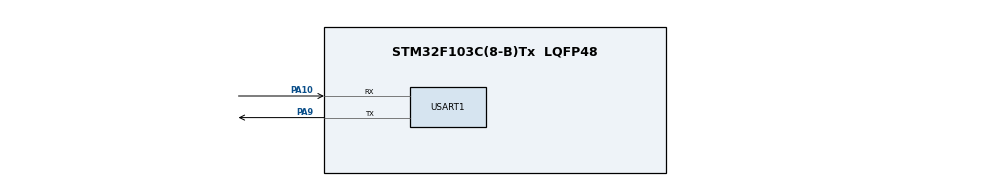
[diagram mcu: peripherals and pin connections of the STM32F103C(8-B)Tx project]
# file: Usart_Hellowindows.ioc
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Mcu.Family=STM32F1
Mcu.Name=STM32F103C(8-B)Tx
Mcu.Package=LQFP48
NVIC.PriorityGroup=NVIC_PRIORITYGROUP_4
NVIC.USART1_IRQn=true\:0\:0\:false\:false\:true\:true\:true\:true
PA10.Mode=Asynchronous
PA10.Signal=USART1_RX
PA13.Mode=Serial_Wire
PA13.Signal=SYS_JTMS-SWDIO
PA14.Mode=Serial_Wire
PA14.Signal=SYS_JTCK-SWCLK
PA9.Mode=Asynchronous
PA9.Signal=USART1_TX
ProjectManager.HeapSize=0x200
ProjectManager.StackSize=0x400
ProjectManager.TargetToolchain=MDK-ARM V5.32
RCC.APB1Freq_Value=8000000
RCC.APB2Freq_Value=8000000
USART1.VirtualMode=VM_ASYNC
board=custom

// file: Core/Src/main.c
/* USER CODE BEGIN Header */
/**
  ******************************************************************************
  * @file           : main.c
  * @brief          : Main program body
  ******************************************************************************
  * @attention
  *
  * Copyright (c) 2023 STMicroelectronics.
  * All rights reserved.
  *
  * This software is licensed under terms that can be found in the LICENSE file
  * in the root directory of this software component.
  * If no LICENSE file comes with this software, it is provided AS-IS.
  *
  ******************************************************************************
  */
/* USER CODE END Header */
#include "main.h"
#include "string.h"

/* USER CODE BEGIN PM */
char message[]="hello Windows!\n";//输出信息
char c;//指令 0:停止  1:开始
char tips[]="CommandError\n";//提示1
char start[]="Start\n";//提示2
char stop[]="Stop\n";//提示3
uint8_t message_flag=0;//标志 0:停止发送 1.开始发送
/* USER CODE END PM */

UART_HandleTypeDef huart1;

void SystemClock_Config(void);
static void MX_GPIO_Init(void);
static void MX_USART1_UART_Init(void);

int main(void)
{
// 初始化STM32和USART
    HAL_Init();
    SystemClock_Config();
    MX_USART1_UART_Init();

    // 启用全局中断
    HAL_NVIC_EnableIRQ(USART1_IRQn);
  /* USER CODE BEGIN 2 */
//设置接受中断
	HAL_UART_Receive_IT(&huart1, (uint8_t *)&c, 1);
  /* USER CODE END 2 */

  /* Infinite loop */
  while (1)
  {
		if (1){
			HAL_UART_Transmit(&huart1, (uint8_t *)&message, strlen(message), 0xFFFF);
		HAL_Delay(1000);
		}
		else {
		}
  }
}

void SystemClock_Config(void)
{
  RCC_OscInitTypeDef RCC_OscInitStruct = {0};
  RCC_ClkInitTypeDef RCC_ClkInitStruct = {0};

  /** Initializes the RCC Oscillators according to the specified parameters
  * in the RCC_OscInitTypeDef structure.
  */
  RCC_OscInitStruct.OscillatorType = RCC_OSCILLATORTYPE_HSI;
  RCC_OscInitStruct.HSIState = RCC_HSI_ON;
  RCC_OscInitStruct.HSICalibrationValue = RCC_HSICALIBRATION_DEFAULT;
  RCC_OscInitStruct.PLL.PLLState = RCC_PLL_NONE;
  if (HAL_RCC_OscConfig(&RCC_OscInitStruct) != HAL_OK)
  {
    Error_Handler();
  }

  /** Initializes the CPU, AHB and APB buses clocks
  */
  RCC_ClkInitStruct.ClockType = RCC_CLOCKTYPE_HCLK|RCC_CLOCKTYPE_SYSCLK
                              |RCC_CLOCKTYPE_PCLK1|RCC_CLOCKTYPE_PCLK2;
  RCC_ClkInitStruct.SYSCLKSource = RCC_SYSCLKSOURCE_HSI;
  RCC_ClkInitStruct.AHBCLKDivider = RCC_SYSCLK_DIV1;
  RCC_ClkInitStruct.APB1CLKDivider = RCC_HCLK_DIV1;
  RCC_ClkInitStruct.APB2CLKDivider = RCC_HCLK_DIV1;

  if (HAL_RCC_ClockConfig(&RCC_ClkInitStruct, FLASH_LATENCY_0) != HAL_OK)
  {
    Error_Handler();
  }
}

static void MX_USART1_UART_Init(void)
{

  huart1.Instance = USART1;
  huart1.Init.BaudRate = 115200;
  huart1.Init.WordLength = UART_WORDLENGTH_8B;
  huart1.Init.StopBits = UART_STOPBITS_1;
  huart1.Init.Parity = UART_PARITY_NONE;
  huart1.Init.Mode = UART_MODE_TX_RX;
  huart1.Init.HwFlowCtl = UART_HWCONTROL_NONE;
  huart1.Init.OverSampling = UART_OVERSAMPLING_16;
  if (HAL_UART_Init(&huart1) != HAL_OK)
  {
    Error_Handler();
  }

}

static void MX_GPIO_Init(void)
{

  /* GPIO Ports Clock Enable */
  __HAL_RCC_GPIOA_CLK_ENABLE();

}

/* USER CODE BEGIN 4 */
void HAL_UART_RxCpltCallback(UART_HandleTypeDef *huart) {
    // 在这里处理接收到的字符
	if (huart->Instance == USART1) {
	    if (c == '#') {
			 // message_flag = 0;  // 暂停发送
       // HAL_UART_Transmit(&huart1, (uint8_t *)stop, strlen(stop), 0xFFFF);
        HAL_UART_Transmit(&huart1, (uint8_t *)&message_flag, sizeof(message_flag), 0xFFFF);  // 发送message_flag的当前值
        HAL_UART_AbortReceive_IT(&huart1);  // 停止继续接收

    } else if (c == '*') {
			 // message_flag = 1;  // 继续发送
       // HAL_UART_Transmit(&huart1, (uint8_t *)start, strlen(start), 0xFFFF);
        HAL_UART_Transmit(&huart1, (uint8_t *)&message_flag, sizeof(message_flag), 0xFFFF);  // 发送message_flag的当前值
        HAL_UART_AbortReceive_IT(&huart1);  // 停止继续接收

    }

    // 启用下一次接收中断
    HAL_UART_Receive_IT(&huart1, (uint8_t *)&c, 1);
	}

}

/* USER CODE END 4 */

void Error_Handler(void)
{
  __disable_irq();
  while (1)
  {
  }
}
